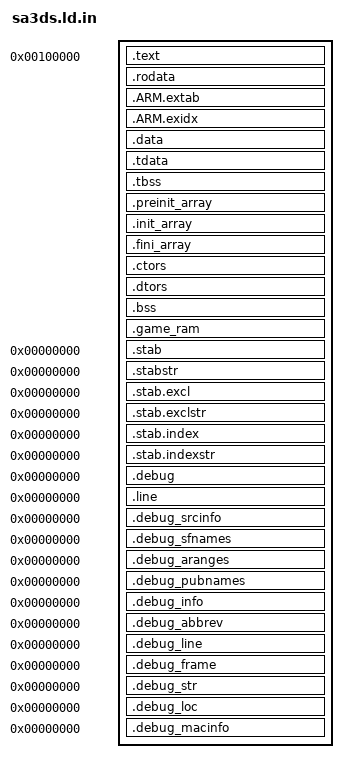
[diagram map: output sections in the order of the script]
/* the 3DS target's linker script: devkitARM's 3dsx.ld, with each program's
 * data and bss in output sections of their own, and the game's RAM reserved
 * above the image. the loader places a .3dsx at 0x00100000 whatever an ELF
 * says, so the program starts there, and 16 MiB at @RAM@ is the one fixed
 * region it can reach; the game's addresses are rebased to it by
 * engine/tools/rambase.py. engine/mk/3ds.mk writes the script from this one,
 * with the programs' sections in place of the lines that name them */
/*--------------------------------------------------------------------------------
	This Source Code Form is subject to the terms of the Mozilla Public License,
	v. 2.0. If a copy of the MPL was not distributed with this file, You can
	obtain one at https://mozilla.org/MPL/2.0/.
--------------------------------------------------------------------------------*/
OUTPUT_FORMAT("elf32-littlearm", "elf32-bigarm", "elf32-littlearm")
OUTPUT_ARCH(arm)
ENTRY(_start)

PHDRS
{
	code   PT_LOAD FLAGS(5) /* Read | Execute */;
	rodata PT_LOAD FLAGS(4) /* Read */;
	data   PT_LOAD FLAGS(6) /* Read | Write */;
	/* the programs' data, in the file alone: 3dsxtool reads PT_LOAD
	   segments, and the build copies these into the RomFS */
	programs 0x60000000;
}

SECTIONS
{
	/* =========== CODE section =========== */

	/* the 3DS target keeps the format's address: a .3dsx loads at 0x00100000 */
	PROVIDE(__start__ = 0x00100000);
	. = __start__;
	/* the code's bounds, which gdfs.c tests an address against */
	PROVIDE(__executable_start = __start__);

	.text ALIGN(0x1000) :
	{
		/* .init */
		KEEP( *(.crt0) )
		KEEP( *(.init) )
		. = ALIGN(4);

		/* .text */
		*(.text)
		*(.text.*)
		*(.glue_7)
		*(.glue_7t)
		*(.stub)
		*(.gnu.warning)
		*(.gnu.linkonce.t*)
		. = ALIGN(4);

		/* .fini */
		KEEP( *(.fini) )
		. = ALIGN(4);
	} : code
	PROVIDE(etext = .);

	/* =========== RODATA section =========== */

	. = ALIGN(0x1000);

	.rodata :
	{
		*(.rodata)
		*(.roda)
		*(.rodata.*)
		*all.rodata*(*)
		*(.gnu.linkonce.r*)
		SORT(CONSTRUCTORS)
		. = ALIGN(4);
		__tdata_align = .;
		LONG (ALIGNOF(.tdata));
		. = ALIGN(4);
	} : rodata

	.ARM.extab : { *(.ARM.extab* .gnu.linkonce.armextab.*) } : rodata
	__exidx_start = .;
	.ARM.exidx : { *(.ARM.exidx* .gnu.linkonce.armexidx.*) } : rodata
	__exidx_end = .;

	/* =========== DATA section =========== */

	. = ALIGN(0x1000);

	.data :
	{
		*(.data)
		*(.data.*)
		*(.gnu.linkonce.d*)
		CONSTRUCTORS
		. = ALIGN(4);
	} : data

	.tdata : ALIGN(4)
	{
		__tdata_lma = .;
		*(.tdata)
		*(.tdata.*)
		*(.gnu.linkonce.td.*)
		. = ALIGN(4);
		__tdata_lma_end = .;
	} : data

	.tbss : ALIGN(4)
	{
		*(.tbss)
		*(.tbss.*)
		*(.gnu.linkonce.tb.*)
		*(.tcommon)
		. = ALIGN(4);
	} : data

	/*
    __tdata_align_val = ABSOLUTE(ALIGNOF(.tdata));
    __tdata_size = ABSOLUTE(SIZEOF(.tdata));
    __tbss_align = ABSOLUTE(ALIGNOF(.tbss));
    __tbss_size = ABSOLUTE(SIZEOF(.tbss));
	*/

	.preinit_array ALIGN(4) :
	{
		PROVIDE (__preinit_array_start = .);
		KEEP (*(.preinit_array))
		PROVIDE (__preinit_array_end = .);
	} : data

	.init_array ALIGN(4) :
	{
		PROVIDE (__init_array_start = .);
		KEEP (*(SORT(.init_array.*)))
		KEEP (*(.init_array))
		PROVIDE (__init_array_end = .);
	} : data

	.fini_array ALIGN(4) :
	{
		PROVIDE (__fini_array_start = .);
		KEEP (*(.fini_array))
		KEEP (*(SORT(.fini_array.*)))
		PROVIDE (__fini_array_end = .);
	} : data

	.ctors ALIGN(4) :
	{
		KEEP (*crtbegin.o(.ctors)) /* MUST be first -- GCC requires it */
		KEEP (*(EXCLUDE_FILE (*crtend.o) .ctors))
		KEEP (*(SORT(.ctors.*)))
		KEEP (*(.ctors))
	} : data

	.dtors ALIGN(4) :
	{
		KEEP (*crtbegin.o(.dtors))
		KEEP (*(EXCLUDE_FILE (*crtend.o) .dtors))
		KEEP (*(SORT(.dtors.*)))
		KEEP (*(.dtors))
	} : data

	__bss_start__ = .;
	.bss ALIGN(4) :
	{
		*(.dynbss)
		*(.bss)
		*(.bss.*)
		*(.gnu.linkonce.b*)
		*(COMMON)

		/* Reserve space for the TLS segment of the main thread.
		   We need (__tls_start - 8) to be aligned the same as .tdata, to account for
		   the 8-byte ARM TLS header. Since the header is not actually used for
		   ARM_TLS_LE32 relocation, we just fake it by subtracting 8 from the data
		   offset.
		 */
		. = 8 + ABSOLUTE(ALIGN(ABSOLUTE(. - 8), MAX(ALIGNOF(.tdata), ALIGNOF(.tbss))));
		__tls_start = .;
		. += SIZEOF(.tdata);

        /* Ensure the alignment of .tbss is accounted for in the total size,
           since SIZEOF(.tdata) doesn't include any padding before .tbss.
         */
        . = ALIGN(ALIGNOF(.tbss));
        . += SIZEOF(.tbss);
		__tls_end = .;
	} : data

	/* ==================
	   ==== Metadata ====
	   ================== */

	/* the game's RAM: 16 MiB at a fixed address, inside the application's
	   region and above the image's data and bss. it is BSS, so the loader maps
	   and zeroes it, and the game's RAM areas are its own addresses, rebased by
	   rambase.py. its base is a multiple of 16 MiB, as the rebase ORs it in */
	ASSERT(. <= @RAM@, "the image's bss passes the game's RAM: raise 3DS_RAM in engine/mk/3ds.mk")
	. = @RAM@;
	.game_ram (NOLOAD) : AT(@RAM@) { __game_ram = .; . += 0x01000000; } : data

	/* each program's data and bss, past the game's RAM, in regions that
	   overlay those of one origin, as engine/tools/overlays.py writes them */
@PROGRAMS@
	__bss_end__ = .;

	__end__ = ABSOLUTE(.) ;

/* Discard sections that difficult post-processing */
	/DISCARD/ : { *(.group .comment .note) }

	/* Stabs debugging sections. */
	.stab          0 : { *(.stab) }
	.stabstr       0 : { *(.stabstr) }
	.stab.excl     0 : { *(.stab.excl) }
	.stab.exclstr  0 : { *(.stab.exclstr) }
	.stab.index    0 : { *(.stab.index) }
	.stab.indexstr 0 : { *(.stab.indexstr) }

	/* DWARF debug sections.
	   Symbols in the DWARF debugging sections are relative to the beginning
	   of the section so we begin them at 0. */

	/* DWARF 1 */
	.debug          0 : { *(.debug) }
	.line           0 : { *(.line) }

	/* GNU DWARF 1 extensions */
	.debug_srcinfo  0 : { *(.debug_srcinfo) }
	.debug_sfnames  0 : { *(.debug_sfnames) }

	/* DWARF 1.1 and DWARF 2 */
	.debug_aranges  0 : { *(.debug_aranges) }
	.debug_pubnames 0 : { *(.debug_pubnames) }

	/* DWARF 2 */
	.debug_info     0 : { *(.debug_info) }
	.debug_abbrev   0 : { *(.debug_abbrev) }
	.debug_line     0 : { *(.debug_line) }
	.debug_frame    0 : { *(.debug_frame) }
	.debug_str      0 : { *(.debug_str) }
	.debug_loc      0 : { *(.debug_loc) }
	.debug_macinfo  0 : { *(.debug_macinfo) }
}
